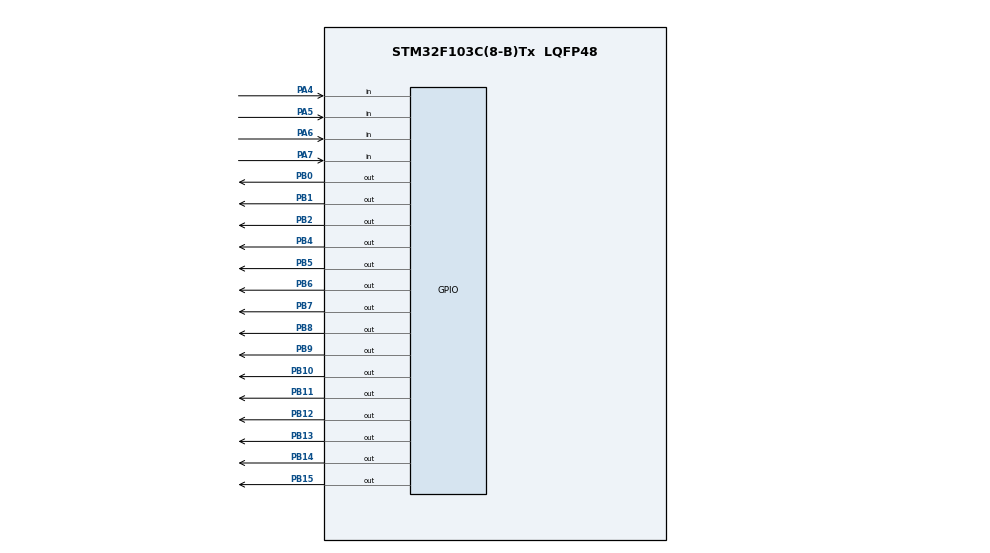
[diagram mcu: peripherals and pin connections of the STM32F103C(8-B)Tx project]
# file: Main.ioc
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Mcu.Family=STM32F1
Mcu.Name=STM32F103C(8-B)Tx
Mcu.Package=LQFP48
NVIC.PriorityGroup=NVIC_PRIORITYGROUP_4
PA13.Mode=JTAG_4_pins
PA13.Signal=SYS_JTMS-SWDIO
PA14.Mode=JTAG_4_pins
PA14.Signal=SYS_JTCK-SWCLK
PA15.Mode=JTAG_4_pins
PA15.Signal=SYS_JTDI
PA4.Signal=GPIO_Input
PA5.Signal=GPIO_Input
PA6.Signal=GPIO_Input
PA7.Signal=GPIO_Input
PB0.Signal=GPIO_Output
PB1.Signal=GPIO_Output
PB10.Signal=GPIO_Output
PB11.Signal=GPIO_Output
PB12.Signal=GPIO_Output
PB13.Signal=GPIO_Output
PB14.Signal=GPIO_Output
PB15.Signal=GPIO_Output
PB2.Signal=GPIO_Output
PB3.Mode=JTAG_4_pins
PB3.Signal=SYS_JTDO-TRACESWO
PB4.Signal=GPIO_Output
PB5.Signal=GPIO_Output
PB6.Signal=GPIO_Output
PB7.Signal=GPIO_Output
PB8.Signal=GPIO_Output
PB9.Signal=GPIO_Output
ProjectManager.HeapSize=0x200
ProjectManager.StackSize=0x400
ProjectManager.TargetToolchain=MDK-ARM V5.32
RCC.APB1Freq_Value=8000000
RCC.APB2Freq_Value=8000000
board=custom

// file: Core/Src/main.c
/* USER CODE BEGIN Header */
/**
  ******************************************************************************
  * @file           : main.c
  * @brief          : Main program body
  ******************************************************************************
  * @attention
  *
  * Copyright (c) 2026 STMicroelectronics.
  * All rights reserved.
  *
  * This software is licensed under terms that can be found in the LICENSE file
  * in the root directory of this software component.
  * If no LICENSE file comes with this software, it is provided AS-IS.
  *
  ******************************************************************************
  */
/* USER CODE END Header */
#include "main.h"

/* USER CODE BEGIN Includes */
#include "aj_bit_reg.h"
/* USER CODE END Includes */

void SystemClock_Config(void);
static void MX_GPIO_Init(void);

/* USER CODE BEGIN 0 */
static inline void Delay_us(uint32_t us){
	while(us--){
			/* 8 MHz -> 1 cycle = 125 ns
				 8 cycles ˜ 1 us */
			__NOP();
			__NOP();
			__NOP();
			__NOP();
			__NOP();
			__NOP();
			__NOP();
			__NOP();
	}
}

static inline void Delay_ms(uint32_t ms){
    while(ms--){
        Delay_us(1000);
    }
}
/* USER CODE END 0 */

int main(void)
{

  /* MCU Configuration--------------------------------------------------------*/

  /* Reset of all peripherals, Initializes the Flash interface and the Systick. */
  LL_APB2_GRP1_EnableClock(LL_APB2_GRP1_PERIPH_AFIO);
  LL_APB1_GRP1_EnableClock(LL_APB1_GRP1_PERIPH_PWR);

  /* System interrupt init*/
  NVIC_SetPriorityGrouping(NVIC_PRIORITYGROUP_4);

  /* SysTick_IRQn interrupt configuration */
  NVIC_SetPriority(SysTick_IRQn, NVIC_EncodePriority(NVIC_GetPriorityGrouping(),15, 0));

  /** NONJTRST: Full SWJ (JTAG-DP + SW-DP) but without NJTRST
  */
  LL_GPIO_AF_Remap_SWJ_NONJTRST();

  /* Configure the system clock */
  SystemClock_Config();

  /* Initialize all configured peripherals */
  MX_GPIO_Init();

  /* Infinite loop */
  /* USER CODE BEGIN WHILE */

// Note: LL_mDelay(500) doesn't work on Proteus

  while (1){
    /* USER CODE END WHILE */

  }
}

void SystemClock_Config(void)
{
  LL_FLASH_SetLatency(LL_FLASH_LATENCY_0);
  while(LL_FLASH_GetLatency()!= LL_FLASH_LATENCY_0)
  {
  }
  LL_RCC_HSI_SetCalibTrimming(16);
  LL_RCC_HSI_Enable();

   /* Wait till HSI is ready */
  while(LL_RCC_HSI_IsReady() != 1)
  {

  }
  LL_RCC_SetAHBPrescaler(LL_RCC_SYSCLK_DIV_1);
  LL_RCC_SetAPB1Prescaler(LL_RCC_APB1_DIV_1);
  LL_RCC_SetAPB2Prescaler(LL_RCC_APB2_DIV_1);
  LL_RCC_SetSysClkSource(LL_RCC_SYS_CLKSOURCE_HSI);

   /* Wait till System clock is ready */
  while(LL_RCC_GetSysClkSource() != LL_RCC_SYS_CLKSOURCE_STATUS_HSI)
  {

  }
  LL_Init1msTick(8000000);
  LL_SetSystemCoreClock(8000000);
}

static void MX_GPIO_Init(void)
{
  LL_GPIO_InitTypeDef GPIO_InitStruct = {0};

  /* GPIO Ports Clock Enable */
  LL_APB2_GRP1_EnableClock(LL_APB2_GRP1_PERIPH_GPIOA);
  LL_APB2_GRP1_EnableClock(LL_APB2_GRP1_PERIPH_GPIOB);

  /**/
  LL_GPIO_ResetOutputPin(GPIOB, LL_GPIO_PIN_0|LL_GPIO_PIN_1|LL_GPIO_PIN_2|LL_GPIO_PIN_10
                          |LL_GPIO_PIN_11|LL_GPIO_PIN_12|LL_GPIO_PIN_13|LL_GPIO_PIN_14
                          |LL_GPIO_PIN_15|LL_GPIO_PIN_4|LL_GPIO_PIN_5|LL_GPIO_PIN_6
                          |LL_GPIO_PIN_7|LL_GPIO_PIN_8|LL_GPIO_PIN_9);

  /**/
  GPIO_InitStruct.Pin = LL_GPIO_PIN_4|LL_GPIO_PIN_5|LL_GPIO_PIN_6|LL_GPIO_PIN_7;
  GPIO_InitStruct.Mode = LL_GPIO_MODE_FLOATING;
  LL_GPIO_Init(GPIOA, &GPIO_InitStruct);

  /**/
  GPIO_InitStruct.Pin = LL_GPIO_PIN_0|LL_GPIO_PIN_1|LL_GPIO_PIN_2|LL_GPIO_PIN_10
                          |LL_GPIO_PIN_11|LL_GPIO_PIN_12|LL_GPIO_PIN_13|LL_GPIO_PIN_14
                          |LL_GPIO_PIN_15|LL_GPIO_PIN_4|LL_GPIO_PIN_5|LL_GPIO_PIN_6
                          |LL_GPIO_PIN_7|LL_GPIO_PIN_8|LL_GPIO_PIN_9;
  GPIO_InitStruct.Mode = LL_GPIO_MODE_OUTPUT;
  GPIO_InitStruct.Speed = LL_GPIO_SPEED_FREQ_LOW;
  GPIO_InitStruct.OutputType = LL_GPIO_OUTPUT_PUSHPULL;
  LL_GPIO_Init(GPIOB, &GPIO_InitStruct);

}

void Error_Handler(void)
{
  __disable_irq();
  while (1)
  {
  }
}
